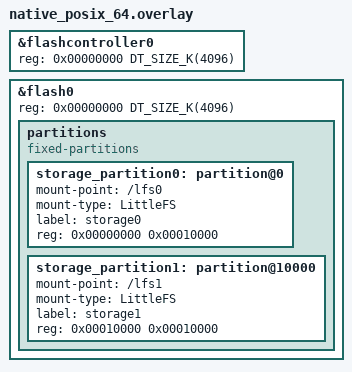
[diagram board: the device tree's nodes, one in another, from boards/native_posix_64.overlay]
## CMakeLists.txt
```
#
# Copyright (c) 2020 Nordic Semiconductor ASA
#
# SPDX-License-Identifier: Apache-2.0

cmake_minimum_required(VERSION 3.13.1)
find_package(Zephyr REQUIRED HINTS $ENV{ZEPHYR_BASE})
project(automount)

FILE(GLOB app_sources src/*.c)
target_sources(app PRIVATE ${app_sources})
```

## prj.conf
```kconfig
CONFIG_FILE_SYSTEM=y
CONFIG_FILE_SYSTEM_LITTLEFS=y
# Required by auto-mount
CONFIG_FS_LITTLEFS_DEFAULT_FSDATA_ALLOCATOR=y
CONFIG_FS_LITTLEFS_DEFAULT_FSDATA_N=2

CONFIG_FILE_SYSTEM_AUTOMOUNT=y

CONFIG_MAIN_STACK_SIZE=4096

CONFIG_FLASH=y
CONFIG_FLASH_MAP=y
CONFIG_FLASH_PAGE_LAYOUT=y

CONFIG_ZTEST=y
CONFIG_ZTEST_STACKSIZE=4096
```

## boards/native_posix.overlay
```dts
/*
 * Copyright (c) 2020 Nordic Semiconductor ASA
 *
 * SPDX-License-Identifier: Apache-2.0
 */

/delete-node/ &storage_partition;
/delete-node/ &scratch_partition;

&flash0 {
	partitions {
		compatible = "fixed-partitions";
		#address-cells = <1>;
		#size-cells = <1>;

		storage_partition: partition@de000 {
			mount-point = "/lfs0";
			mount-type = "LittleFS";
			label = "storage";
			reg = <0x000de000 0x00010000>;
		};
		storage1_partition: partition@1de000 {
			mount-point = "/lfs1";
			mount-type = "LittleFS";
			label = "storage1";
			reg = <0x001de000 0x00010000>;
		};
	};
};
```

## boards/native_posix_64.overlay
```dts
/*
 * Copyright (c) 2020 Nordic Semiconductor ASA
 *
 * SPDX-License-Identifier: Apache-2.0
 */

&flashcontroller0 {
	reg = <0x00000000 DT_SIZE_K(4096)>;
};

&flash0 {
	reg = <0x00000000 DT_SIZE_K(4096)>;
	partitions {
		compatible = "fixed-partitions";
		#address-cells = <1>;
		#size-cells = <1>;

		storage_partition0: partition@0 {
			mount-point = "/lfs0";
			mount-type = "LittleFS";
			label = "storage0";
			reg = <0x00000000 0x00010000>;
		};
		storage_partition1: partition@10000 {
			mount-point = "/lfs1";
			mount-type = "LittleFS";
			label = "storage1";
			reg = <0x00010000 0x00010000>;
		};
	};
};
```

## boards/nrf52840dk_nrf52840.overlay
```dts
/*
 * Copyright (c) 2020 Nordic Semiconductor ASA
 *
 * SPDX-License-Identifier: Apache-2.0
 */

/delete-node/ &storage_partition;
/delete-node/ &scratch_partition;

&flash0 {
	partitions {
		compatible = "fixed-partitions";
		#address-cells = <1>;
		#size-cells = <1>;

		storage_partition: partition@f8000 {
			label = "storage";
			reg = <0x000f8000 0x00004000>;
		};
		storage1_partition: partition@fc000 {
			label = "storage1";
			reg = <0x000fc000 0x00004000>;
		};
	};
};
```

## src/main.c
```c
/*
 * Copyright (c) 2020 Nordic Semiconductor ASA
 *
 * SPDX-License-Identifier: Apache-2.0
 */

#include <string.h>
#include <ztest.h>
#include <fs/fs.h>

int test_open_lfs0(void)
{
	struct fs_file_t f =  { 0 };

	if (fs_open(&f, "/lfs0/file", FS_O_CREATE) != 0) {
		return TC_FAIL;
	}

	fs_close(&f);

	return TC_PASS;
}

static int test_open_lfs1(void)
{
	struct fs_file_t f =  { 0 };

	if (fs_open(&f, "/lfs1/file", FS_O_CREATE) != 0) {
		return TC_FAIL;
	}

	fs_close(&f);

	return TC_PASS;
}

void test_all(void)
{
	zassert_equal(test_open_lfs0(),
		      TC_PASS,
		      "Failed to create file on /lfs0");
	zassert_equal(test_open_lfs1(),
		      TC_PASS,
		      "Failed to create file on /lfs1");
}

void test_main(void)
{
	ztest_test_suite(automount_test,
			 ztest_unit_test(test_all)
			 );
	ztest_run_test_suite(automount_test);
}
```
